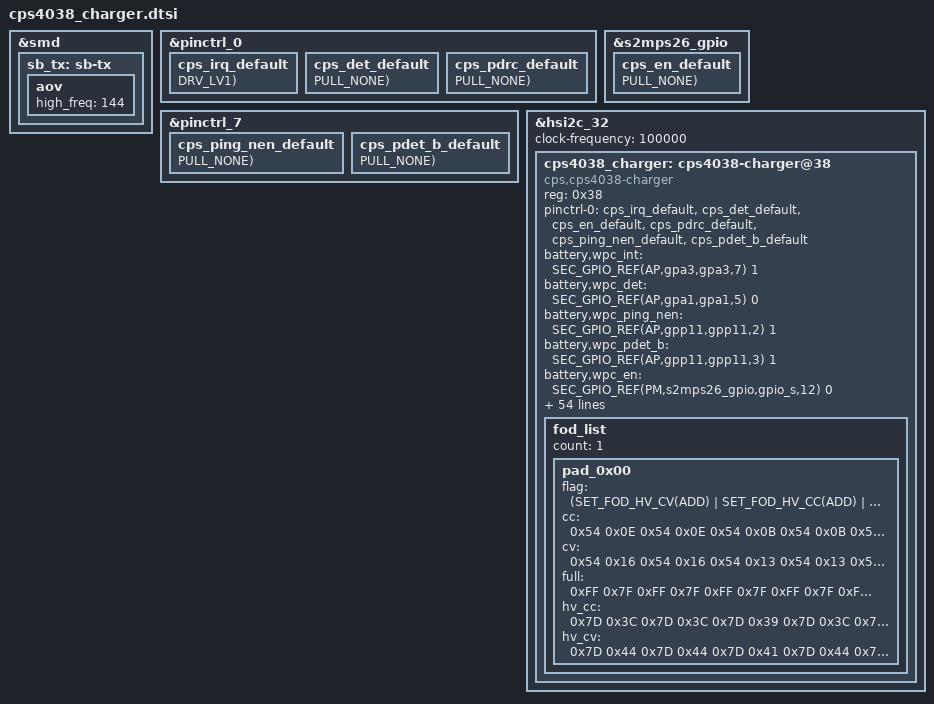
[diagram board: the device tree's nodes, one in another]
#include <dt-bindings/battery/sec-battery.h>

&smd {
	sb_tx: sb-tx {
	       aov {
		       high_freq = <144>;
	       };
       };
};

&pinctrl_0 {
	cps_irq_default: cps_irq_default {
		GPIO_CONFIG_PUD_DRV(AP,gpa3,gpa3,7, FUNC_INPUT_WAKEUP, PULL_NONE, DRV_LV1);
	};
};

&pinctrl_0 {
	cps_det_default: cps_det_default {
		GPIO_CONFIG_PUD(AP,gpa1,gpa1,5, FUNC_INPUT_WAKEUP, PULL_NONE);
	};
};

&s2mps26_gpio {
	cps_en_default: cps_en_default {
		GPIO_CONFIG_PUD(PM,s2mps26_gpio,gpio_s,12, FUNC_OUTPUT_LOW, PULL_NONE);
	};
};

#if 1
&pinctrl_0 {
	cps_pdrc_default: cps_pdrc_default {
		GPIO_CONFIG_PUD(AP,gpa2,gpa2,1, FUNC_INPUT_WAKEUP, PULL_NONE);
	};
};
#endif

#if 1
&pinctrl_7 {
	cps_ping_nen_default: cps_ping_nen_default {
		GPIO_CONFIG_PUD(AP,gpp11,gpp11,2, FUNC_OUTPUT_HIGH, PULL_NONE);
	};
};
#endif

#if 1
&pinctrl_7 {
	cps_pdet_b_default: cps_pdet_b_default {
		GPIO_CONFIG_PUD(AP,gpp11,gpp11,3, FUNC_INPUT_WAKEUP, PULL_NONE);
	};
};
#endif

&hsi2c_32 {
	#address-cells = <1>;
	#size-cells = <0>;
	status = "okay";
	clock-frequency = <100000>;

	cps4038_charger: cps4038-charger@38 {
		compatible = "cps,cps4038-charger";
		reg = <0x38>;
		status = "okay";

		pinctrl-names = "default";

#if 1
		pinctrl-0 = <&cps_irq_default &cps_det_default &cps_en_default &cps_pdrc_default &cps_ping_nen_default &cps_pdet_b_default>;
#else
		pinctrl-0 = <&cps_irq_default &cps_det_default &cps_en_default &cps_pdrc_default>;
#endif
		battery,wpc_int = <SEC_GPIO_REF(AP,gpa3,gpa3,7) 1>; /* MFC_AP_INT */
		battery,wpc_det = <SEC_GPIO_REF(AP,gpa1,gpa1,5) 0>; /* WPC_DET */
#if 0
		battery,mst_pwr_en = <SEC_GPIO_REF(${cps_pwr_en_gpio}) 0>; /* MST_PWR_EN */
#endif
#if 1
		battery,wpc_ping_nen = <SEC_GPIO_REF(AP,gpp11,gpp11,2) 1>; /* PING_NEN */
#endif
#if 1
		battery,wpc_pdet_b = <SEC_GPIO_REF(AP,gpp11,gpp11,3) 1>; /* PDET_B */
#endif
		battery,wpc_en = <SEC_GPIO_REF(PM,s2mps26_gpio,gpio_s,12) 0>; /* WPC_EN */
#if 1
		battery,wpc_pdrc = <SEC_GPIO_REF(AP,gpa2,gpa2,1) 1>; /* VRECT_INT */
#endif

		battery,charger_name = "max77705-charger";
		battery,fuelgauge_name = "max77705-fuelgauge";
		battery,wireless_charger_name = "cps4038-charger";
		battery,wc_cover_rpp = <0x44>;
		battery,phone_fod_threshold = <0x3b>;
		battery,wireless20_vout_list = <WIRELESS_VOUT_11V /* 0xA0 */
						WIRELESS_VOUT_11V /* 0xA1 */
						WIRELESS_VOUT_11V /* 0xA2 */
						WIRELESS_VOUT_11V /* 0xA3 */
						WIRELESS_VOUT_11V /* 0xA4 */
						WIRELESS_VOUT_11V>; /* 0xA5 */
		battery,wireless20_vrect_list = <MFC_AFC_CONF_12V_TX
						MFC_AFC_CONF_12_5V_TX
						MFC_AFC_CONF_12_5V_TX
						MFC_AFC_CONF_12_5V_TX
						MFC_AFC_CONF_12_5V_TX
						MFC_AFC_CONF_12_5V_TX>;
		battery,wireless20_max_power_list = <SEC_WIRELESS_RX_POWER_12W
						SEC_WIRELESS_RX_POWER_15W
						SEC_WIRELESS_RX_POWER_15W
						SEC_WIRELESS_RX_POWER_15W
						SEC_WIRELESS_RX_POWER_15W
						SEC_WIRELESS_RX_POWER_15W>;

		battery,buds_fod_ta_thresh = <0x0898>; /* 2200mW */
		battery,wpc_vout_ctrl_full = <WIRELESS_VOUT_5V_STEP>;
		battery,mis_align_guide;
		battery,mis_align_target_vout = <5000>;
	};
};

/* /home/dpi/qb5_8814/workspace/P4_1716/android/kernel/kmodule/battery/stable/r11/wireless/cps4038/cps4038_charger.r11s.dtsi */
#include <dt-bindings/battery/sec-battery.h>

&cps4038_charger {
	battery,mst_iset_pcr = <0x06>;
	battery,unknown_cmb_ctrl;
	battery,wireless20_vout_list = <WIRELESS_VOUT_9V /* 0xA0 */
					WIRELESS_VOUT_11V /* 0xA1 */
					WIRELESS_VOUT_11V /* 0xA2 */
					WIRELESS_VOUT_11V /* 0xA3 */
					WIRELESS_VOUT_11V /* 0xA4 */
					WIRELESS_VOUT_11V>; /* 0xA5 */
	battery,wireless20_vrect_list = <MFC_AFC_CONF_12V_TX
					MFC_AFC_CONF_12_5V_TX
					MFC_AFC_CONF_12_5V_TX
					MFC_AFC_CONF_12_5V_TX
					MFC_AFC_CONF_12_5V_TX
					MFC_AFC_CONF_12_5V_TX>;
	battery,wireless20_max_power_list = <SEC_WIRELESS_RX_POWER_12W
					SEC_WIRELESS_RX_POWER_15W
					SEC_WIRELESS_RX_POWER_15W
					SEC_WIRELESS_RX_POWER_15W
					SEC_WIRELESS_RX_POWER_15W
					SEC_WIRELESS_RX_POWER_15W>;
	battery,tx_fod_gain = <0x83>;
	battery,tx_fod_offset = <0xFF38>;
	battery,phone_fod_ta_thresh = <0x03E8>;/* 1000mW */
	battery,buds_fod_ta_thresh = <0x0898>; /* 2200mW */
	battery,gear_op_freq = <0x0596>; /* 143kHZ */
	battery,tx_gear_min_op_freq_delay = <4000>;
	battery,gear_min_op_freq = <1300>;

	battery,default_clamp_volt;

	battery,wireless20_iec_qfod_enable = <0x0>;
	battery,wireless20_iec_q_thresh_1 = <0x46>;
	battery,wireless20_iec_q_thresh_2 = <0x3c>;
	battery,wireless20_iec_fres_thresh_1 = <0x47>;
	battery,wireless20_iec_fres_thresh_2 = <0x55>;
	battery,wireless20_iec_power_limit_thresh = <0x190>;
	battery,wireless20_iec_ploss_thresh_1 = <0x0fa>;
	battery,wireless20_iec_ploss_thresh_2 = <0x384>;
	battery,wireless20_iec_ploss_freq_thresh_1 = <0xff>;
	battery,wireless20_iec_ploss_freq_thresh_2 = <0xff>;
	battery,wireless20_iec_ta_power_limit_thresh = <0x258>;
	battery,wireless20_iec_ta_ploss_thresh_1 = <0x190>;
	battery,wireless20_iec_ta_ploss_thresh_2 = <0x4b0>;
	battery,wireless20_iec_ta_ploss_freq_thresh_1 = <0xff>;
	battery,wireless20_iec_ta_ploss_freq_thresh_2 = <0xff>;
	battery,wireless20_iec_ploss_fod_enable = <0x1>;
	battery,wireless20_iec_pwm_duty_thresh = <0x23>;
	battery,wireless20_iec_ta_pwm_duty_thresh = <0x1e>;

	fod_list {
		count = <1>;

		pad_0x00 { /* DEFAULT */
			flag = <(SET_FOD_HV_CV(ADD) | SET_FOD_HV_CC(ADD) | SET_FOD_FULL(ADD) | SET_FOD_CV(ADD) | SET_FOD_CC(ADD))>;
			cc = <0x54 0x0E 0x54 0x0E 0x54 0x0B 0x54 0x0B 0x54 0x0B
				0x54 0x0B 0x54 0x0B 0x54 0x0C 0x54 0x0C 0x54 0x0C>;
			cv = <0x54 0x16 0x54 0x16 0x54 0x13 0x54 0x13 0x54 0x13
				0x54 0x13 0x54 0x13 0x54 0x14 0x54 0x14 0x54 0x14>;
			full = <0xFF 0x7F 0xFF 0x7F 0xFF 0x7F 0xFF 0x7F 0xFF 0x7F
				0xFF 0x7F 0xFF 0x7F 0xFF 0x7F 0xFF 0x7F 0xFF 0x7F>;
			hv_cc = <0x7D 0x3C 0x7D 0x3C 0x7D 0x39 0x7D 0x3C 0x7D 0x3C
				0x7D 0x3C 0x7D 0x3C 0x7D 0x3C 0x7D 0x3C 0x7D 0x3C>;
			hv_cv = <0x7D 0x44 0x7D 0x44 0x7D 0x41 0x7D 0x44 0x7D 0x44
				0x7D 0x44 0x7D 0x44 0x7D 0x44 0x7D 0x44 0x7D 0x44>;
		};
	};
};
